# SKEAZ1284 register map
File version: 1.6
Registers are 8-bit, read-write, reset 0x0 unless marked. A register's access mark holds for its fields unless they carry their own. Offsets are from the block's base; [hi:lo] are bit positions; {n}, {i} and the like mark numbered series; 'fields as' and 'values as' point back to an identical list.

## FTM0 — FlexTimer Module
Base 0x40038000; register names take the prefix FTM0_
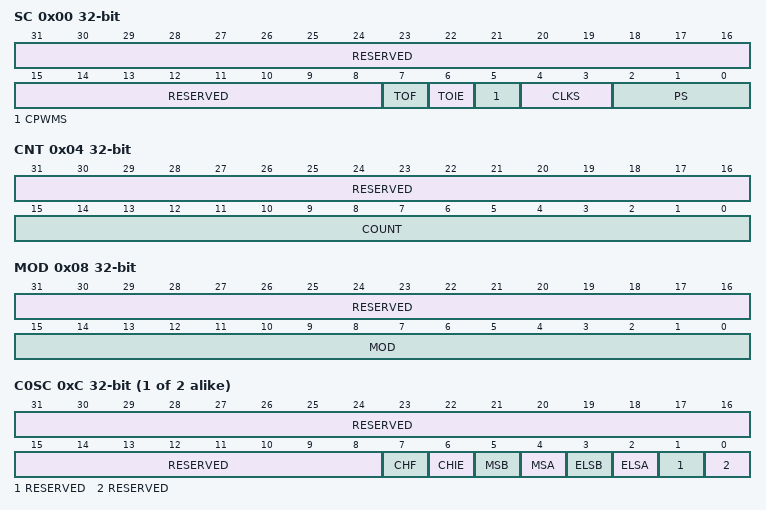
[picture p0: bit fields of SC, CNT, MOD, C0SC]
0x00 SC 32-bit — Status And Control
  [31:8] RESERVED ro
  [7] TOF ro — Timer Overflow Flag
    0=FTM counter has not overflowed; 1=FTM counter has overflowed
  [6] TOIE — Timer Overflow Interrupt Enable
    0=Disable TOF interrupts. Use software polling.; 1=Enable TOF interrupts. An interrupt is generated when TOF equals one.
  [5] CPWMS — Center-Aligned PWM Select
    0=FTM counter operates in Up Counting mode; 1=FTM counter operates in Up-Down Counting mode
  [4:3] CLKS — Clock Source Selection
    0=No clock selected. This in effect disables the FTM counter.; 1=System clock; 2=Fixed frequency clock; 3=External clock
  [2:0] PS — Prescale Factor Selection
    0=Divide by 1; 1=Divide by 2; 2=Divide by 4; 3=Divide by 8; 4=Divide by 16; 5=Divide by 32; 6=Divide by 64; 7=Divide by 128
0x04 CNT 32-bit — Counter
  [31:16] RESERVED ro
  [15:0] COUNT — Counter Value
0x08 MOD 32-bit — Modulo
  [31:16] RESERVED, [15:0] MOD
{0xC+8i} C{i}SC (i=0..1) 32-bit — Channel (n) Status And Control
  [31:8] RESERVED ro
  [7] CHF ro — Channel Flag
    0=No channel event has occurred; 1=A channel event has occurred
  [6] CHIE — Channel Interrupt Enable
    0=Disable channel interrupts. Use software polling.; 1=Enable channel interrupts
  [5] MSB — Channel Mode Select
  [4] MSA — Channel Mode Select
  [3] ELSB — Edge or Level Select
  [2] ELSA — Edge or Level Select
  [1] RESERVED ro
  [0] RESERVED ro
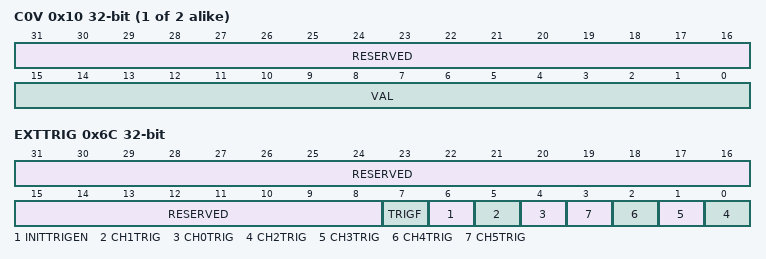
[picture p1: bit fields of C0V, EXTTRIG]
{0x10+8i} C{i}V (i=0..1) 32-bit — Channel (n) Value
  [31:16] RESERVED ro
  [15:0] VAL — Channel Value
0x6C EXTTRIG 32-bit — FTM External Trigger
  [31:8] RESERVED
  [7] TRIGF ro — Channel Trigger Flag
    0=No channel trigger was generated; 1=A channel trigger was generated
  [6] INITTRIGEN — Initialization Trigger Enable
    0=The generation of initialization trigger is disabled; 1=The generation of initialization trigger is enabled
  [5] CH1TRIG — Channel 1 Trigger Enable
    0=The generation of the channel trigger is disabled; 1=The generation of the channel trigger is enabled
  [4] CH0TRIG — Channel 0 Trigger Enable
    values as CH1TRIG
  [n-2] CH{n}TRIG (n=2..5) — Channel {n} Trigger Enable
    values as CH1TRIG

## FTM1 — FlexTimer Module
Base 0x40039000; register names take the prefix FTM1_
Registers as FTM0, without EXTTRIG.

## RTC — Real-time counter
Base 0x4003D000; register names take the prefix RTC_
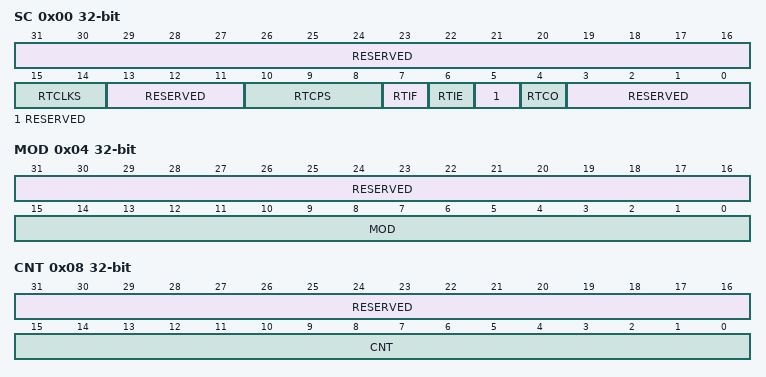
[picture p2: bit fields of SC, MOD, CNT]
0x00 SC 32-bit — RTC Status and Control Register
  [31:16] RESERVED ro
  [15:14] RTCLKS — Real-Time Clock Source Select
    0=External clock source; 1=Real-time clock source is 1 kHz (LPOCLK); 2=Internal reference clock (ICSIRCLK); 3=Bus clock
  [13:11] RESERVED ro
  [10:8] RTCPS — Real-Time Clock Prescaler Select
    0=Off; 1=If RTCLKS = x0, it is 1; if RTCLKS = x1, it is 128; 2=If RTCLKS = x0, it is 2; if RTCLKS = x1, it is 256; 3=If RTCLKS = x0, it is 4; if RTCLKS = x1, it is 512; 4=If RTCLKS = x0, it is 8; if RTCLKS = x1, it is 1024; 5=If RTCLKS = x0, it is 16; if RTCLKS = x1, it is 2048; 6=If RTCLKS = x0, it is 32; if RTCLKS = x1, it is 100; 7=If RTCLKS = x0, it is 64; if RTCLKS = x1, it is 1000
  [7] RTIF — Real-Time Interrupt Flag
    0=RTC counter has not reached the value in the RTC modulo register; 1=RTC counter has reached the value in the RTC modulo register
  [6] RTIE — Real-Time Interrupt Enable
    0=Real-time interrupt requests are disabled. Use software polling.; 1=Real-time interrupt requests are enabled
  [5] RESERVED ro
  [4] RTCO — Real-Time Counter Output
    0=Real-time counter output disabled; 1=Real-time counter output enabled
  [3:0] RESERVED ro
0x04 MOD 32-bit — RTC Modulo Register
  [31:16] RESERVED ro
  [15:0] MOD — RTC Modulo
0x08 CNT 32-bit ro — RTC Counter Register
  [31:16] RESERVED
  [15:0] CNT — RTC Count
